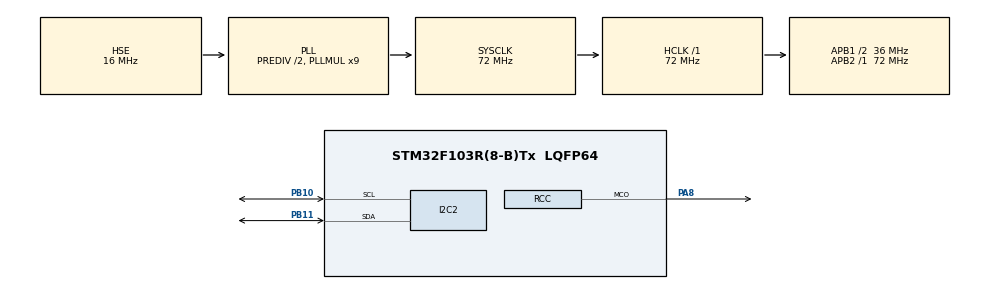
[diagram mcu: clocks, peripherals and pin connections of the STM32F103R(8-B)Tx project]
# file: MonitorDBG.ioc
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I2C2.I2C_Mode=I2C_Fast
Mcu.Family=STM32F1
Mcu.Name=STM32F103R(8-B)Tx
Mcu.Package=LQFP64
NVIC.PriorityGroup=NVIC_PRIORITYGROUP_4
PA13.Mode=Serial_Wire
PA13.Signal=SYS_JTMS-SWDIO
PA14.Mode=Serial_Wire
PA14.Signal=SYS_JTCK-SWCLK
PA8.Mode=Clock-out
PA8.Signal=RCC_MCO
PB10.Mode=I2C
PB10.Signal=I2C2_SCL
PB11.Mode=I2C
PB11.Signal=I2C2_SDA
PD0-OSC_IN.Mode=HSE-External-Oscillator
PD0-OSC_IN.Signal=RCC_OSC_IN
PD1-OSC_OUT.Mode=HSE-External-Oscillator
PD1-OSC_OUT.Signal=RCC_OSC_OUT
ProjectManager.HeapSize=0x200
ProjectManager.StackSize=0x400
ProjectManager.TargetToolchain=STM32CubeIDE
RCC.AHBFreq_Value=72000000
RCC.APB1CLKDivider=RCC_HCLK_DIV2
RCC.APB1Freq_Value=36000000
RCC.APB1TimFreq_Value=72000000
RCC.APB2Freq_Value=72000000
RCC.APB2TimFreq_Value=72000000
RCC.HCLKFreq_Value=72000000
RCC.HSEDivPLL=RCC_HSE_PREDIV_DIV2
RCC.HSE_VALUE=16000000
RCC.PLLMUL=RCC_PLL_MUL9
RCC.PLLSourceVirtual=RCC_PLLSOURCE_HSE
RCC.RCC_MCOSource=RCC_MCO1SOURCE_PLLCLK
RCC.SYSCLKFreq_VALUE=72000000
RCC.SYSCLKSource=RCC_SYSCLKSOURCE_PLLCLK
RCC.USBFreq_Value=72000000
TIM1.Period=0xffff-1
TIM1.Prescaler=72-1
VP_TIM1_VS_ClockSourceINT.Mode=Internal
board=custom

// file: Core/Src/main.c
/* USER CODE BEGIN Header */
/**
  ******************************************************************************
  * @file           : main.c
  * @brief          : Main program body
  ******************************************************************************
  * @attention
  *
  * Copyright (c) 2024 STMicroelectronics.
  * All rights reserved.
  *
  * This software is licensed under terms that can be found in the LICENSE file
  * in the root directory of this software component.
  * If no LICENSE file comes with this software, it is provided AS-IS.
  *
  ******************************************************************************
  */
/* USER CODE END Header */
#include "main.h"

/* USER CODE BEGIN Includes */
#include <stdio.h>
#include <stdbool.h>
#include "lcd1602_i2c_lib.h"

extern char lcd1602_tx_buffer[40];
uint8_t flag = 0;
uint8_t procent;
int counter = -56421;
uint32_t Delay = 100;
float counter_float = 0.0f;

uint16_t i = 0;
unsigned long T1, T2;

const uint8_t symbol_celsius[8] = {
		0x07,	// 00000111
		0x05,	// 00000101
		0x07,	// 00000111
		0x00,	// 00000000
		0x00,	// 00000000
		0x00,	// 00000000
		0x00,	// 00000000
		0x00	// 00000000
		};
/*
#define RS_PORT GPIOB
#define RS_PIN RS_Pin_GPIO_PIN_PB12
#define RW_PORT GPIOB
#define RW_PIN RW_Pin_GPIO_PIN_PB15
#define EN_PORT GPIOB
#define EN_PIN E_Pin_GPIO_PIN_PB13_Pin
#define D4_PORT GPIOB
#define D4_PIN D4_Pin_GPIO_PIN_PB8_Pin
#define D5_PORT GPIOB
#define D5_PIN D5_Pin_GPIO_PIN_PB9_Pin
#define D6_PORT GPIOB
#define D6_PIN D6_Pin_GPIO_PIN_PB10_Pin
#define D7_PORT GPIOB
#define D7_PIN D7_Pin_GPIO_PIN_PB11_Pin
*/
/* USER CODE END Includes */

I2C_HandleTypeDef hi2c2;

TIM_HandleTypeDef htim1;

void SystemClock_Config(void);
static void MX_GPIO_Init(void);
static void MX_TIM1_Init(void);
static void MX_I2C2_Init(void);

/* USER CODE BEGIN 0 */

int _write(int file, uint8_t *ptr, int len) {

	for (int DataIdx = 0; DataIdx < len; DataIdx++) {
		ITM_SendChar(*ptr++);
	}
	return len;
}

/* USER CODE END 0 */

int main(void)
{

  /* MCU Configuration--------------------------------------------------------*/

  /* Reset of all peripherals, Initializes the Flash interface and the Systick. */
  HAL_Init();

  /* Configure the system clock */
  SystemClock_Config();

  /* Initialize all configured peripherals */
  MX_GPIO_Init();
  MX_TIM1_Init();
  MX_I2C2_Init();
  /* USER CODE BEGIN 2 */
  HAL_Delay(100);
  lcd1602_Init();
  lcd1602_SetCursor(0,0);
  lcd1602_Print_text("Hello world");

  /* USER CODE END 2 */

  /* Infinite loop */
  	while (1)
  	{
  	}

  			/* USER CODE BEGIN 3 */

  /* USER CDE END 3 */
}

void SystemClock_Config(void)
{
  RCC_OscInitTypeDef RCC_OscInitStruct = {0};
  RCC_ClkInitTypeDef RCC_ClkInitStruct = {0};

  /** Initializes the RCC Oscillators according to the specified parameters
  * in the RCC_OscInitTypeDef structure.
  */
  RCC_OscInitStruct.OscillatorType = RCC_OSCILLATORTYPE_HSE;
  RCC_OscInitStruct.HSEState = RCC_HSE_ON;
  RCC_OscInitStruct.HSEPredivValue = RCC_HSE_PREDIV_DIV2;
  RCC_OscInitStruct.HSIState = RCC_HSI_ON;
  RCC_OscInitStruct.PLL.PLLState = RCC_PLL_ON;
  RCC_OscInitStruct.PLL.PLLSource = RCC_PLLSOURCE_HSE;
  RCC_OscInitStruct.PLL.PLLMUL = RCC_PLL_MUL9;
  if (HAL_RCC_OscConfig(&RCC_OscInitStruct) != HAL_OK)
  {
    Error_Handler();
  }

  /** Initializes the CPU, AHB and APB buses clocks
  */
  RCC_ClkInitStruct.ClockType = RCC_CLOCKTYPE_HCLK|RCC_CLOCKTYPE_SYSCLK
                              |RCC_CLOCKTYPE_PCLK1|RCC_CLOCKTYPE_PCLK2;
  RCC_ClkInitStruct.SYSCLKSource = RCC_SYSCLKSOURCE_PLLCLK;
  RCC_ClkInitStruct.AHBCLKDivider = RCC_SYSCLK_DIV1;
  RCC_ClkInitStruct.APB1CLKDivider = RCC_HCLK_DIV2;
  RCC_ClkInitStruct.APB2CLKDivider = RCC_HCLK_DIV1;

  if (HAL_RCC_ClockConfig(&RCC_ClkInitStruct, FLASH_LATENCY_2) != HAL_OK)
  {
    Error_Handler();
  }
  HAL_RCC_MCOConfig(RCC_MCO, RCC_MCO1SOURCE_PLLCLK, RCC_MCODIV_1);
}

static void MX_I2C2_Init(void)
{

  hi2c2.Instance = I2C2;
  hi2c2.Init.ClockSpeed = 100000;
  hi2c2.Init.DutyCycle = I2C_DUTYCYCLE_2;
  hi2c2.Init.OwnAddress1 = 0;
  hi2c2.Init.AddressingMode = I2C_ADDRESSINGMODE_7BIT;
  hi2c2.Init.DualAddressMode = I2C_DUALADDRESS_DISABLE;
  hi2c2.Init.OwnAddress2 = 0;
  hi2c2.Init.GeneralCallMode = I2C_GENERALCALL_DISABLE;
  hi2c2.Init.NoStretchMode = I2C_NOSTRETCH_DISABLE;
  if (HAL_I2C_Init(&hi2c2) != HAL_OK)
  {
    Error_Handler();
  }

}

static void MX_TIM1_Init(void)
{

  TIM_ClockConfigTypeDef sClockSourceConfig = {0};
  TIM_MasterConfigTypeDef sMasterConfig = {0};

  htim1.Instance = TIM1;
  htim1.Init.Prescaler = 72-1;
  htim1.Init.CounterMode = TIM_COUNTERMODE_UP;
  htim1.Init.Period = 0xffff-1;
  htim1.Init.ClockDivision = TIM_CLOCKDIVISION_DIV1;
  htim1.Init.RepetitionCounter = 0;
  htim1.Init.AutoReloadPreload = TIM_AUTORELOAD_PRELOAD_DISABLE;
  if (HAL_TIM_Base_Init(&htim1) != HAL_OK)
  {
    Error_Handler();
  }
  sClockSourceConfig.ClockSource = TIM_CLOCKSOURCE_INTERNAL;
  if (HAL_TIM_ConfigClockSource(&htim1, &sClockSourceConfig) != HAL_OK)
  {
    Error_Handler();
  }
  sMasterConfig.MasterOutputTrigger = TIM_TRGO_RESET;
  sMasterConfig.MasterSlaveMode = TIM_MASTERSLAVEMODE_DISABLE;
  if (HAL_TIMEx_MasterConfigSynchronization(&htim1, &sMasterConfig) != HAL_OK)
  {
    Error_Handler();
  }

}

static void MX_GPIO_Init(void)
{
  GPIO_InitTypeDef GPIO_InitStruct = {0};

  /* GPIO Ports Clock Enable */
  __HAL_RCC_GPIOD_CLK_ENABLE();
  __HAL_RCC_GPIOB_CLK_ENABLE();
  __HAL_RCC_GPIOA_CLK_ENABLE();

  /*Configure GPIO pin : PA8 */
  GPIO_InitStruct.Pin = GPIO_PIN_8;
  GPIO_InitStruct.Mode = GPIO_MODE_AF_PP;
  GPIO_InitStruct.Speed = GPIO_SPEED_FREQ_LOW;
  HAL_GPIO_Init(GPIOA, &GPIO_InitStruct);

}

void Error_Handler(void)
{
  __disable_irq();
  while (1)
  {
  }
}
